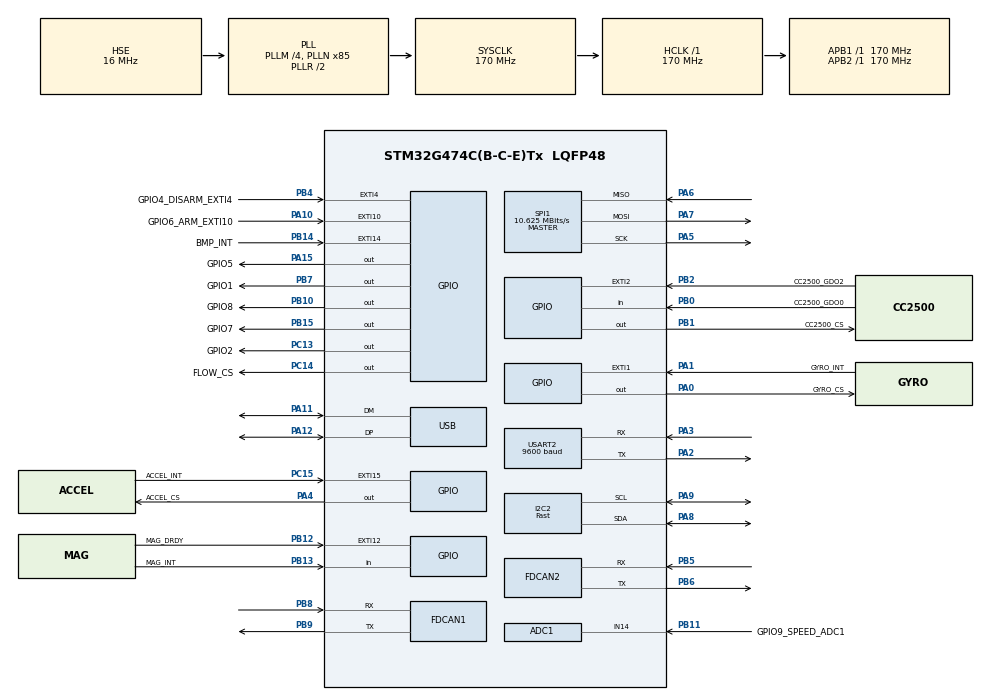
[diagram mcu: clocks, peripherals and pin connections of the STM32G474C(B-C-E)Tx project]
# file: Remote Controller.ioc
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ADC1.Channel-1\#ChannelRegularConversion=ADC_CHANNEL_14
ADC1.ClockPrescaler=ADC_CLOCK_ASYNC_DIV256
ADC1.ContinuousConvMode=ENABLE
ADC1.DMAContinuousRequests=ENABLE
ADC1.NbrOfConversionFlag=1
ADC1.OffsetNumber-1\#ChannelRegularConversion=ADC_OFFSET_NONE
ADC1.Rank-1\#ChannelRegularConversion=1
ADC1.SamplingTime-1\#ChannelRegularConversion=ADC_SAMPLETIME_92CYCLES_5
ADC1.master=1
Dma.ADC1.2.Direction=DMA_PERIPH_TO_MEMORY
Dma.ADC1.2.EventEnable=DISABLE
Dma.ADC1.2.Instance=DMA1_Channel3
Dma.ADC1.2.MemDataAlignment=DMA_MDATAALIGN_HALFWORD
Dma.ADC1.2.MemInc=DMA_MINC_ENABLE
Dma.ADC1.2.Mode=DMA_CIRCULAR
Dma.ADC1.2.PeriphDataAlignment=DMA_PDATAALIGN_HALFWORD
Dma.ADC1.2.PeriphInc=DMA_PINC_DISABLE
Dma.ADC1.2.Polarity=HAL_DMAMUX_REQ_GEN_RISING
Dma.ADC1.2.Priority=DMA_PRIORITY_LOW
Dma.ADC1.2.RequestNumber=1
Dma.ADC1.2.SignalID=NONE
Dma.ADC1.2.SyncEnable=DISABLE
Dma.ADC1.2.SyncPolarity=HAL_DMAMUX_SYNC_NO_EVENT
Dma.ADC1.2.SyncRequestNumber=1
Dma.ADC1.2.SyncSignalID=NONE
Dma.Request0=USART2_RX
Dma.Request1=USART2_TX
Dma.Request2=ADC1
Dma.USART2_RX.0.Direction=DMA_PERIPH_TO_MEMORY
Dma.USART2_RX.0.EventEnable=DISABLE
Dma.USART2_RX.0.Instance=DMA1_Channel1
Dma.USART2_RX.0.MemDataAlignment=DMA_MDATAALIGN_BYTE
Dma.USART2_RX.0.MemInc=DMA_MINC_ENABLE
Dma.USART2_RX.0.Mode=DMA_NORMAL
Dma.USART2_RX.0.PeriphDataAlignment=DMA_PDATAALIGN_BYTE
Dma.USART2_RX.0.PeriphInc=DMA_PINC_DISABLE
Dma.USART2_RX.0.Polarity=HAL_DMAMUX_REQ_GEN_RISING
Dma.USART2_RX.0.Priority=DMA_PRIORITY_LOW
Dma.USART2_RX.0.RequestNumber=1
Dma.USART2_RX.0.SignalID=NONE
Dma.USART2_RX.0.SyncEnable=DISABLE
Dma.USART2_RX.0.SyncPolarity=HAL_DMAMUX_SYNC_NO_EVENT
Dma.USART2_RX.0.SyncRequestNumber=1
Dma.USART2_RX.0.SyncSignalID=NONE
Dma.USART2_TX.1.Direction=DMA_MEMORY_TO_PERIPH
Dma.USART2_TX.1.EventEnable=DISABLE
Dma.USART2_TX.1.Instance=DMA1_Channel2
Dma.USART2_TX.1.MemDataAlignment=DMA_MDATAALIGN_BYTE
Dma.USART2_TX.1.MemInc=DMA_MINC_ENABLE
Dma.USART2_TX.1.Mode=DMA_NORMAL
Dma.USART2_TX.1.PeriphDataAlignment=DMA_PDATAALIGN_BYTE
Dma.USART2_TX.1.PeriphInc=DMA_PINC_DISABLE
Dma.USART2_TX.1.Polarity=HAL_DMAMUX_REQ_GEN_RISING
Dma.USART2_TX.1.Priority=DMA_PRIORITY_LOW
Dma.USART2_TX.1.RequestNumber=1
Dma.USART2_TX.1.SignalID=NONE
Dma.USART2_TX.1.SyncEnable=DISABLE
Dma.USART2_TX.1.SyncPolarity=HAL_DMAMUX_SYNC_NO_EVENT
Dma.USART2_TX.1.SyncRequestNumber=1
Dma.USART2_TX.1.SyncSignalID=NONE
FDCAN1.AutoRetransmission=ENABLE
FDCAN1.CalculateBaudRateNominal=999999
FDCAN1.CalculateTimeBitNominal=1000
FDCAN1.CalculateTimeQuantumNominal=58.82352941176471
FDCAN1.NominalPrescaler=10
FDCAN1.NominalTimeSeg1=13
FDCAN1.NominalTimeSeg2=3
FDCAN1.StdFiltersNbr=1
FDCAN1.TransmitPause=ENABLE
FDCAN2.AutoRetransmission=ENABLE
FDCAN2.CalculateBaudRateNominal=999999
FDCAN2.CalculateTimeBitNominal=1000
FDCAN2.CalculateTimeQuantumNominal=58.82352941176471
FDCAN2.NominalPrescaler=10
FDCAN2.NominalTimeSeg1=13
FDCAN2.NominalTimeSeg2=3
FDCAN2.StdFiltersNbr=1
FDCAN2.TransmitPause=ENABLE
FREERTOS.Mutexes01=spi1Mutex,Static,spi1MutexControlBlock,Depleted;usbMutex,Static,usbMutexControlBlock,Depleted
FREERTOS.Queues01=rcControllerQueue,64,ThreadInput,0,Static,rcControllerQueueBuffer,rcControllerQueueControlBlock
FREERTOS.Tasks01=rcControllerTask,24,2048,start_rc_controller_task,Default,NULL,Static,rcControllerTaskBuffer,rcControllerTaskControlBlock
FREERTOS.configENABLE_FPU=1
FREERTOS.configGENERATE_RUN_TIME_STATS=1
FREERTOS.configMAX_TASK_NAME_LEN=30
FREERTOS.configMINIMAL_STACK_SIZE=256
FREERTOS.configTOTAL_HEAP_SIZE=65536
FREERTOS.configUSE_NEWLIB_REENTRANT=1
FREERTOS.configUSE_STATS_FORMATTING_FUNCTIONS=1
I2C2.I2C_Speed_Mode=I2C_Fast
I2C2.Timing=0x40621236
Mcu.Family=STM32G4
Mcu.Name=STM32G474C(B-C-E)Tx
Mcu.Package=LQFP48
NVIC.DMA1_Channel1_IRQn=true\:5\:0\:false\:false\:true\:true\:false\:true\:true
NVIC.DMA1_Channel2_IRQn=true\:5\:0\:false\:false\:true\:true\:false\:true\:true
NVIC.DMA1_Channel3_IRQn=true\:5\:0\:false\:false\:true\:true\:false\:true\:true
NVIC.EXTI15_10_IRQn=true\:5\:0\:false\:false\:true\:true\:true\:true\:true
NVIC.EXTI1_IRQn=true\:5\:0\:false\:false\:true\:true\:true\:true\:true
NVIC.EXTI2_IRQn=true\:5\:0\:false\:false\:true\:true\:true\:true\:true
NVIC.EXTI4_IRQn=true\:5\:0\:false\:false\:true\:true\:true\:true\:true
NVIC.FDCAN1_IT0_IRQn=true\:5\:0\:false\:false\:true\:true\:true\:true\:true
NVIC.FDCAN2_IT0_IRQn=true\:5\:0\:false\:false\:true\:true\:true\:true\:true
NVIC.PriorityGroup=NVIC_PRIORITYGROUP_4
NVIC.TIM1_UP_TIM16_IRQn=true\:5\:0\:false\:false\:true\:true\:true\:true\:true
NVIC.TIM6_DAC_IRQn=true\:15\:0\:false\:false\:true\:false\:false\:true\:true
NVIC.TimeBase=TIM6_DAC_IRQn
NVIC.TimeBaseIP=TIM6
NVIC.USART2_IRQn=true\:5\:0\:false\:false\:true\:true\:true\:true\:true
NVIC.USB_LP_IRQn=true\:5\:0\:false\:false\:true\:true\:false\:true\:true
PA0.GPIO_Label=GYRO_CS
PA0.GPIO_PuPd=GPIO_PULLUP
PA0.PinState=GPIO_PIN_SET
PA0.Signal=GPIO_Output
PA1.GPIO_Label=GYRO_INT
PA1.GPIO_PuPd=GPIO_PULLDOWN
PA1.Signal=GPXTI1
PA10.GPIO_Label=GPIO6_ARM_EXTI10
PA10.Signal=GPXTI10
PA11.Mode=Device
PA11.Signal=USB_DM
PA12.Mode=Device
PA12.Signal=USB_DP
PA13.Mode=Trace_Asynchronous_SW
PA13.Signal=SYS_JTMS-SWDIO
PA14.Mode=Trace_Asynchronous_SW
PA14.Signal=SYS_JTCK-SWCLK
PA15.GPIO_Label=GPIO5
PA15.PinState=GPIO_PIN_SET
PA15.Signal=GPIO_Output
PA2.Mode=Asynchronous
PA2.Signal=USART2_TX
PA3.Mode=Asynchronous
PA3.Signal=USART2_RX
PA4.GPIO_Label=ACCEL_CS
PA4.GPIO_PuPd=GPIO_PULLUP
PA4.PinState=GPIO_PIN_SET
PA4.Signal=GPIO_Output
PA5.Mode=Full_Duplex_Master
PA5.Signal=SPI1_SCK
PA6.Mode=Full_Duplex_Master
PA6.Signal=SPI1_MISO
PA7.Mode=Full_Duplex_Master
PA7.Signal=SPI1_MOSI
PA8.Mode=I2C
PA8.Signal=I2C2_SDA
PA9.Mode=I2C
PA9.Signal=I2C2_SCL
PB0.GPIO_Label=CC2500_GDO0
PB0.Signal=GPIO_Input
PB1.GPIO_Label=CC2500_CS
PB1.GPIO_PuPd=GPIO_PULLUP
PB1.PinState=GPIO_PIN_SET
PB1.Signal=GPIO_Output
PB10.GPIO_Label=GPIO8
PB10.Signal=GPIO_Output
PB11.GPIO_Label=GPIO9_SPEED_ADC1
PB11.Mode=IN14-Single-Ended
PB11.Signal=ADC1_IN14
PB12.GPIO_Label=MAG_DRDY
PB12.GPIO_PuPd=GPIO_PULLDOWN
PB12.Signal=GPXTI12
PB13.GPIO_Label=MAG_INT
PB13.Signal=GPIO_Input
PB14.GPIO_Label=BMP_INT
PB14.GPIO_PuPd=GPIO_PULLDOWN
PB14.Signal=GPXTI14
PB15.GPIO_Label=GPIO7
PB15.Signal=GPIO_Output
PB2.GPIO_Label=CC2500_GDO2
PB2.GPIO_ModeDefaultEXTI=GPIO_MODE_IT_FALLING
PB2.Signal=GPXTI2
PB3.Mode=Trace_Asynchronous_SW
PB3.Signal=SYS_JTDO-SWO
PB4.GPIO_Label=GPIO4_DISARM_EXTI4
PB4.Signal=GPXTI4
PB5.Mode=FDCAN_Activate
PB5.Signal=FDCAN2_RX
PB6.Mode=FDCAN_Activate
PB6.Signal=FDCAN2_TX
PB7.GPIO_Label=GPIO1
PB7.Signal=GPIO_Output
PB8-BOOT0.Mode=FDCAN_Activate
PB8-BOOT0.Signal=FDCAN1_RX
PB9.Mode=FDCAN_Activate
PB9.Signal=FDCAN1_TX
PC13.GPIO_Label=GPIO2
PC13.Signal=GPIO_Output
PC14-OSC32_IN.GPIO_Label=FLOW_CS
PC14-OSC32_IN.Signal=GPIO_Output
PC15-OSC32_OUT.GPIO_Label=ACCEL_INT
PC15-OSC32_OUT.GPIO_PuPd=GPIO_PULLDOWN
PC15-OSC32_OUT.Signal=GPXTI15
PF0-OSC_IN.Mode=HSE-External-Oscillator
PF0-OSC_IN.Signal=RCC_OSC_IN
PF1-OSC_OUT.Mode=HSE-External-Oscillator
PF1-OSC_OUT.Signal=RCC_OSC_OUT
ProjectManager.HeapSize=0x200
ProjectManager.StackSize=0x400
ProjectManager.TargetToolchain=STM32CubeIDE
RCC.ADC12Freq_Value=170000000
RCC.ADC345Freq_Value=170000000
RCC.AHBFreq_Value=170000000
RCC.APB1Freq_Value=170000000
RCC.APB1TimFreq_Value=170000000
RCC.APB2Freq_Value=170000000
RCC.APB2TimFreq_Value=170000000
RCC.CK48CLockSelection=RCC_USBCLKSOURCE_HSI48
RCC.CortexFreq_Value=170000000
RCC.EXTERNAL_CLOCK_VALUE=12288000
RCC.HCLKFreq_Value=170000000
RCC.HSE_VALUE=16000000
RCC.HSI48_VALUE=48000000
RCC.HSI_VALUE=16000000
RCC.LSE_VALUE=32768
RCC.PLLM=RCC_PLLM_DIV4
RCC.PLLN=85
RCC.PLLQ=RCC_PLLQ_DIV8
RCC.PLLSourceVirtual=RCC_PLLSOURCE_HSE
RCC.SYSCLKFreq_VALUE=170000000
RCC.SYSCLKSource=RCC_SYSCLKSOURCE_PLLCLK
RCC.USBFreq_Value=48000000
RCC.VCOOutputFreq_Value=340000000
SPI1.BaudRatePrescaler=SPI_BAUDRATEPRESCALER_16
SPI1.CalculateBaudRate=10.625 MBits/s
SPI1.DataSize=SPI_DATASIZE_8BIT
SPI1.Direction=SPI_DIRECTION_2LINES
SPI1.Mode=SPI_MODE_MASTER
SPI1.VirtualType=VM_MASTER
STMicroelectronics.X-CUBE-MEMS1.11.1.0.SensorsJjSTM32IiMotionFXIiLibraryJjCore=true
TIM16.PeriodNoDither=1700 - 1
USART2.BaudRate=9600
USART2.VirtualMode-Asynchronous=VM_ASYNC
USB_DEVICE.APP_TX_DATA_SIZE=2048
USB_DEVICE.CLASS_NAME_FS=CDC
USB_DEVICE.MANUFACTURER_STRING=Nikolai Philipenko
USB_DEVICE.PRODUCT_STRING_CDC_FS=NP1 RC Controller
USB_DEVICE.VirtualMode=Cdc
USB_DEVICE.VirtualModeFS=Cdc_FS
VP_CRC_VS_CRC.Mode=CRC_Activate
VP_FREERTOS_VS_CMSIS_V2.Mode=CMSIS_V2
VP_STMicroelectronics.X-CUBE-MEMS1_VS_SensorsJjSTM32IiMotionFXIiLibrary_2.9.0_11.1.0.Mode=SensorsJjSTM32IiMotionFXIiLibrary
VP_SYS_VS_DBSignals.Mode=DisableDeadBatterySignals
VP_SYS_VS_tim6.Mode=TIM6
VP_TIM16_VS_ClockSourceINT.Mode=Enable_Timer
VP_USB_DEVICE_VS_USB_DEVICE_CDC_FS.Mode=CDC_FS
board=custom

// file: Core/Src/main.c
/* USER CODE BEGIN Header */
/**
  ******************************************************************************
  * @file           : main.c
  * @brief          : Main program body
  ******************************************************************************
  * @attention
  *
  * Copyright (c) 2024 STMicroelectronics.
  * All rights reserved.
  *
  * This software is licensed under terms that can be found in the LICENSE file
  * in the root directory of this software component.
  * If no LICENSE file comes with this software, it is provided AS-IS.
  *
  ******************************************************************************
  */
/* USER CODE END Header */
#include "main.h"
#include "cmsis_os.h"
#include "adc.h"
#include "crc.h"
#include "dma.h"
#include "fdcan.h"
#include "i2c.h"
#include "spi.h"
#include "tim.h"
#include "usart.h"
#include "usb_device.h"
#include "gpio.h"

/* USER CODE BEGIN PV */
volatile unsigned long ulHighFrequencyTimerCounts;
const int THREAD_START_DELAY_MS = 650;
/* USER CODE END PV */

void SystemClock_Config(void);
void MX_FREERTOS_Init(void);

int main(void)
{

  /* MCU Configuration--------------------------------------------------------*/

  /* Reset of all peripherals, Initializes the Flash interface and the Systick. */
  HAL_Init();

  /* Configure the system clock */
  SystemClock_Config();

  /* Initialize all configured peripherals */
  MX_GPIO_Init();
  MX_DMA_Init();
  MX_FDCAN1_Init();
  MX_FDCAN2_Init();
  MX_I2C2_Init();
  MX_SPI1_Init();
  MX_USART2_UART_Init();
  MX_TIM16_Init();
  MX_CRC_Init();
  MX_ADC1_Init();
  /* USER CODE BEGIN 2 */
  MX_USB_Device_Init();

  /* USER CODE END 2 */

  /* Init scheduler */
  osKernelInitialize();

  /* Call init function for freertos objects (in cmsis_os2.c) */
  MX_FREERTOS_Init();

  /* Start scheduler */
  osKernelStart();

  /* We should never get here as control is now taken by the scheduler */

  /* Infinite loop */
  while (1)
  {

  }
}

void SystemClock_Config(void)
{
  RCC_OscInitTypeDef RCC_OscInitStruct = {0};
  RCC_ClkInitTypeDef RCC_ClkInitStruct = {0};

  /** Configure the main internal regulator output voltage
  */
  HAL_PWREx_ControlVoltageScaling(PWR_REGULATOR_VOLTAGE_SCALE1_BOOST);

  /** Initializes the RCC Oscillators according to the specified parameters
  * in the RCC_OscInitTypeDef structure.
  */
  RCC_OscInitStruct.OscillatorType = RCC_OSCILLATORTYPE_HSI48|RCC_OSCILLATORTYPE_HSE;
  RCC_OscInitStruct.HSEState = RCC_HSE_ON;
  RCC_OscInitStruct.HSI48State = RCC_HSI48_ON;
  RCC_OscInitStruct.PLL.PLLState = RCC_PLL_ON;
  RCC_OscInitStruct.PLL.PLLSource = RCC_PLLSOURCE_HSE;
  RCC_OscInitStruct.PLL.PLLM = RCC_PLLM_DIV4;
  RCC_OscInitStruct.PLL.PLLN = 85;
  RCC_OscInitStruct.PLL.PLLP = RCC_PLLP_DIV2;
  RCC_OscInitStruct.PLL.PLLQ = RCC_PLLQ_DIV8;
  RCC_OscInitStruct.PLL.PLLR = RCC_PLLR_DIV2;
  if (HAL_RCC_OscConfig(&RCC_OscInitStruct) != HAL_OK)
  {
    Error_Handler();
  }

  /** Initializes the CPU, AHB and APB buses clocks
  */
  RCC_ClkInitStruct.ClockType = RCC_CLOCKTYPE_HCLK|RCC_CLOCKTYPE_SYSCLK
                              |RCC_CLOCKTYPE_PCLK1|RCC_CLOCKTYPE_PCLK2;
  RCC_ClkInitStruct.SYSCLKSource = RCC_SYSCLKSOURCE_PLLCLK;
  RCC_ClkInitStruct.AHBCLKDivider = RCC_SYSCLK_DIV1;
  RCC_ClkInitStruct.APB1CLKDivider = RCC_HCLK_DIV1;
  RCC_ClkInitStruct.APB2CLKDivider = RCC_HCLK_DIV1;

  if (HAL_RCC_ClockConfig(&RCC_ClkInitStruct, FLASH_LATENCY_4) != HAL_OK)
  {
    Error_Handler();
  }
}

/* USER CODE BEGIN 4 */

void configureTimerForRunTimeStats(void)
{
    ulHighFrequencyTimerCounts = 0;
    HAL_TIM_Base_Start_IT(&htim16);
}

unsigned long getRunTimeCounterValue(void)
{
	return ulHighFrequencyTimerCounts;
}

/* USER CODE END 4 */

void HAL_TIM_PeriodElapsedCallback(TIM_HandleTypeDef *htim)
{
  if (htim->Instance == TIM6) {
    HAL_IncTick();
  }
}

void Error_Handler(void)
{
  __disable_irq();
  while (1)
  {
  }
}

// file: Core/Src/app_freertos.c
/* USER CODE BEGIN Header */
/**
  ******************************************************************************
  * File Name          : app_freertos.c
  * Description        : Code for freertos applications
  ******************************************************************************
  * @attention
  *
  * Copyright (c) 2024 STMicroelectronics.
  * All rights reserved.
  *
  * This software is licensed under terms that can be found in the LICENSE file
  * in the root directory of this software component.
  * If no LICENSE file comes with this software, it is provided AS-IS.
  *
  ******************************************************************************
  */
/* USER CODE END Header */

#include "FreeRTOS.h"
#include "task.h"
#include "main.h"
#include "cmsis_os.h"

/* USER CODE BEGIN Includes */

#include "fdcan.h"

#include "Threads/rc_controller.hpp"
#include "Threads/rc_controller_types.hpp"

/* USER CODE END Includes */

typedef StaticTask_t osStaticThreadDef_t;
typedef StaticQueue_t osStaticMessageQDef_t;
typedef StaticSemaphore_t osStaticMutexDef_t;

/* Definitions for rcControllerTask */
osThreadId_t rcControllerTaskHandle;
uint32_t rcControllerTaskBuffer[ 2048 ];
osStaticThreadDef_t rcControllerTaskControlBlock;
const osThreadAttr_t rcControllerTask_attributes = {
  .name = "rcControllerTask",
  .stack_mem = &rcControllerTaskBuffer[0],
  .stack_size = sizeof(rcControllerTaskBuffer),
  .cb_mem = &rcControllerTaskControlBlock,
  .cb_size = sizeof(rcControllerTaskControlBlock),
  .priority = (osPriority_t) osPriorityNormal,
};
/* Definitions for rcControllerQueue */
osMessageQueueId_t rcControllerQueueHandle;
uint8_t rcControllerQueueBuffer[ 64 * sizeof( ThreadInput ) ];
osStaticMessageQDef_t rcControllerQueueControlBlock;
const osMessageQueueAttr_t rcControllerQueue_attributes = {
  .name = "rcControllerQueue",
  .cb_mem = &rcControllerQueueControlBlock,
  .cb_size = sizeof(rcControllerQueueControlBlock),
  .mq_mem = &rcControllerQueueBuffer,
  .mq_size = sizeof(rcControllerQueueBuffer)
};
/* Definitions for spi1Mutex */
osMutexId_t spi1MutexHandle;
osStaticMutexDef_t spi1MutexControlBlock;
const osMutexAttr_t spi1Mutex_attributes = {
  .name = "spi1Mutex",
  .cb_mem = &spi1MutexControlBlock,
  .cb_size = sizeof(spi1MutexControlBlock),
};
/* Definitions for usbMutex */
osMutexId_t usbMutexHandle;
osStaticMutexDef_t usbMutexControlBlock;
const osMutexAttr_t usbMutex_attributes = {
  .name = "usbMutex",
  .cb_mem = &usbMutexControlBlock,
  .cb_size = sizeof(usbMutexControlBlock),
};

void start_rc_controller_task(void *argument);

void MX_FREERTOS_Init(void); /* (MISRA C 2004 rule 8.1) */

/* Hook prototypes */
void configureTimerForRunTimeStats(void);
unsigned long getRunTimeCounterValue(void);

/* USER CODE BEGIN 1 */
/* Functions needed when configGENERATE_RUN_TIME_STATS is on */
__weak void configureTimerForRunTimeStats(void) { }
__weak unsigned long getRunTimeCounterValue(void) { return 0; }
/* USER CODE END 1 */

void MX_FREERTOS_Init(void) {
  /* Create the mutex(es) */
  /* creation of spi1Mutex */
  spi1MutexHandle = osMutexNew(&spi1Mutex_attributes);

  /* creation of usbMutex */
  usbMutexHandle = osMutexNew(&usbMutex_attributes);

  /* Create the queue(s) */
  /* creation of rcControllerQueue */
  rcControllerQueueHandle = osMessageQueueNew (64, sizeof(ThreadInput), &rcControllerQueue_attributes);

  /* Create the thread(s) */
  /* creation of rcControllerTask */
  rcControllerTaskHandle = osThreadNew(start_rc_controller_task, NULL, &rcControllerTask_attributes);

}

void start_rc_controller_task(void *argument)
{
  /* USER CODE BEGIN start_rc_controller_task */
  /* Infinite loop */
  rc_controller_thread();
  /* USER CODE END start_rc_controller_task */
}
